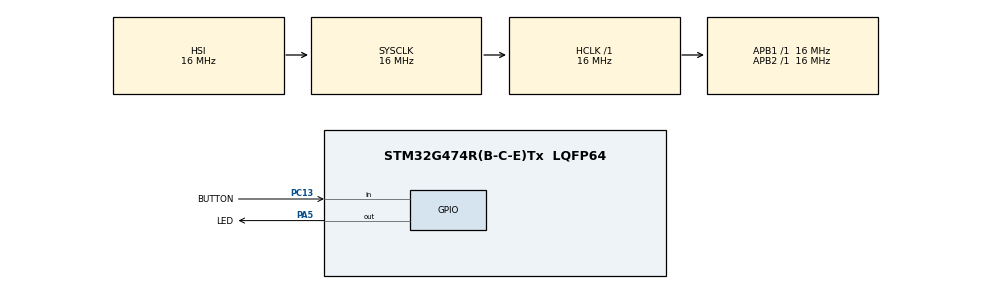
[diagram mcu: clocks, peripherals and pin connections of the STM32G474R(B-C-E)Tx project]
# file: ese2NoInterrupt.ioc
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Mcu.Family=STM32G4
Mcu.Name=STM32G474R(B-C-E)Tx
Mcu.Package=LQFP64
NVIC.PriorityGroup=NVIC_PRIORITYGROUP_4
PA5.GPIO_Label=LED
PA5.Signal=GPIO_Output
PC13.GPIO_Label=BUTTON
PC13.GPIO_Mode=GPIO_MODE_INPUT
PC13.GPIO_PuPd=GPIO_PULLDOWN
PC13.Signal=GPIO_Input
ProjectManager.HeapSize=0x200
ProjectManager.StackSize=0x400
ProjectManager.TargetToolchain=STM32CubeIDE
RCC.AHBFreq_Value=16000000
RCC.APB1Freq_Value=16000000
RCC.APB1TimFreq_Value=16000000
RCC.APB2Freq_Value=16000000
RCC.APB2TimFreq_Value=16000000
RCC.CortexFreq_Value=16000000
RCC.EXTERNAL_CLOCK_VALUE=12288000
RCC.HCLKFreq_Value=16000000
RCC.HSE_VALUE=8000000
RCC.HSI48_VALUE=48000000
RCC.HSI_VALUE=16000000
RCC.LSE_VALUE=32768
RCC.SYSCLKFreq_VALUE=16000000
RCC.USBFreq_Value=64000000
RCC.VCOOutputFreq_Value=128000000
VP_SYS_VS_DBSignals.Mode=DisableDeadBatterySignals
board=custom

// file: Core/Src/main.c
/* USER CODE BEGIN Header */
/**
  ******************************************************************************
  * @file           : main.c
  * @brief          : Main program body
  ******************************************************************************
  * @attention
  *
  * Copyright (c) 2026 STMicroelectronics.
  * All rights reserved.
  *
  * This software is licensed under terms that can be found in the LICENSE file
  * in the root directory of this software component.
  * If no LICENSE file comes with this software, it is provided AS-IS.
  *
  ******************************************************************************
  */
/* USER CODE END Header */
#include "main.h"
#include "gpio.h"

/* USER CODE BEGIN Includes */
#include "stdbool.h"

/* USER CODE END Includes */

/* USER CODE BEGIN PV */
uint16_t mood=0;
bool blinking=false;

/* USER CODE END PV */

void SystemClock_Config(void);

int main(void)
{

  /* MCU Configuration--------------------------------------------------------*/

  /* Reset of all peripherals, Initializes the Flash interface and the Systick. */
  HAL_Init();

  /* Configure the system clock */
  SystemClock_Config();

  /* Initialize all configured peripherals */
  MX_GPIO_Init();

  /* Infinite loop */
  /* USER CODE BEGIN WHILE */
  while (1)
  {
	  //Pull down mode, reset se non premuto, set se premuto
		if (HAL_GPIO_ReadPin(BUTTON_GPIO_Port, BUTTON_Pin) == GPIO_PIN_SET) {
			//se il bottone è premuto

			while(HAL_GPIO_ReadPin(BUTTON_GPIO_Port, GPIO_PIN_13) == GPIO_PIN_RESET);

			HAL_Delay(20); // Debouncing anche al rilascio
			if(mood==2){
				mood=0;
			}else{
				mood++;
			}
		}
		switch (mood) {
		//il led è 1hz

		case (0):
			HAL_Delay(500);
			break;
		case (1):
			HAL_Delay(250);
			break;
		case (2):
			HAL_Delay(125);
			break;
		}
		HAL_GPIO_TogglePin(LED_GPIO_Port, LED_Pin);
    /* USER CODE END WHILE */

  }
}

void SystemClock_Config(void)
{
  RCC_OscInitTypeDef RCC_OscInitStruct = {0};
  RCC_ClkInitTypeDef RCC_ClkInitStruct = {0};

  /** Configure the main internal regulator output voltage
  */
  HAL_PWREx_ControlVoltageScaling(PWR_REGULATOR_VOLTAGE_SCALE1);

  /** Initializes the RCC Oscillators according to the specified parameters
  * in the RCC_OscInitTypeDef structure.
  */
  RCC_OscInitStruct.OscillatorType = RCC_OSCILLATORTYPE_HSI;
  RCC_OscInitStruct.HSIState = RCC_HSI_ON;
  RCC_OscInitStruct.HSICalibrationValue = RCC_HSICALIBRATION_DEFAULT;
  RCC_OscInitStruct.PLL.PLLState = RCC_PLL_NONE;
  if (HAL_RCC_OscConfig(&RCC_OscInitStruct) != HAL_OK)
  {
    Error_Handler();
  }

  /** Initializes the CPU, AHB and APB buses clocks
  */
  RCC_ClkInitStruct.ClockType = RCC_CLOCKTYPE_HCLK|RCC_CLOCKTYPE_SYSCLK
                              |RCC_CLOCKTYPE_PCLK1|RCC_CLOCKTYPE_PCLK2;
  RCC_ClkInitStruct.SYSCLKSource = RCC_SYSCLKSOURCE_HSI;
  RCC_ClkInitStruct.AHBCLKDivider = RCC_SYSCLK_DIV1;
  RCC_ClkInitStruct.APB1CLKDivider = RCC_HCLK_DIV1;
  RCC_ClkInitStruct.APB2CLKDivider = RCC_HCLK_DIV1;

  if (HAL_RCC_ClockConfig(&RCC_ClkInitStruct, FLASH_LATENCY_0) != HAL_OK)
  {
    Error_Handler();
  }
}

void Error_Handler(void)
{
  __disable_irq();
  while (1)
  {
  }
}
